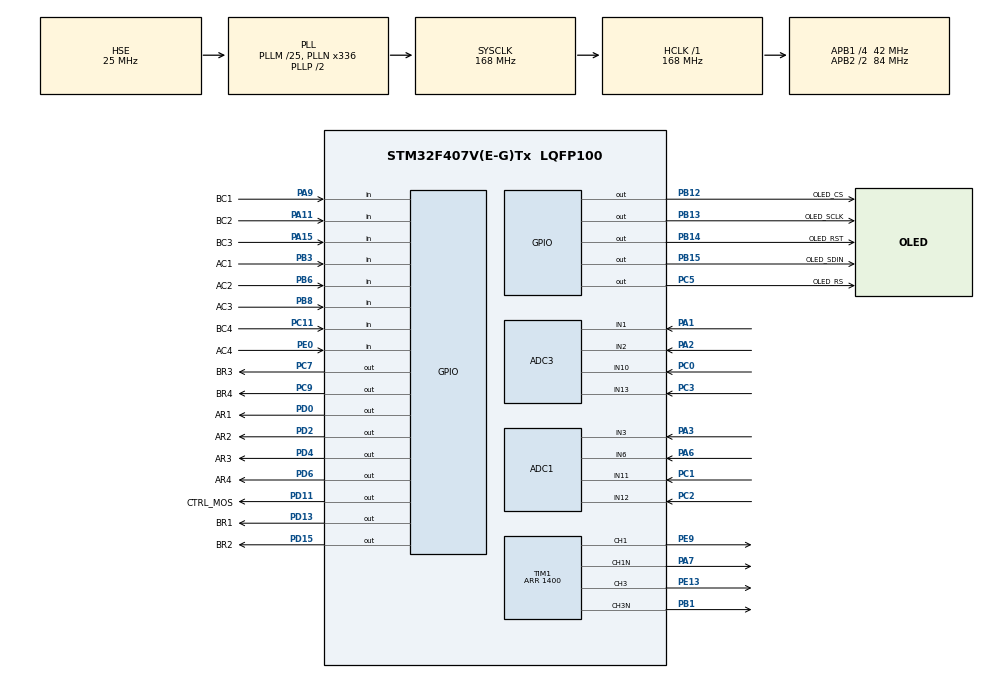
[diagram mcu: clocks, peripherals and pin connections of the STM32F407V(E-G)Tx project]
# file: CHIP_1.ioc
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ADC1.Channel-0\#ChannelRegularConversion=ADC_CHANNEL_3
ADC1.Channel-1\#ChannelRegularConversion=ADC_CHANNEL_3
ADC1.Channel-2\#ChannelRegularConversion=ADC_CHANNEL_11
ADC1.Channel-3\#ChannelRegularConversion=ADC_CHANNEL_12
ADC1.ClockPrescaler=ADC_CLOCK_SYNC_PCLK_DIV8
ADC1.DMAContinuousRequests=ENABLE
ADC1.EOCSelection=ADC_EOC_SEQ_CONV
ADC1.ExternalTrigConv=ADC_EXTERNALTRIGCONV_T1_CC2
ADC1.NbrOfConversion=4
ADC1.NbrOfConversionFlag=1
ADC1.Rank-0\#ChannelRegularConversion=1
ADC1.Rank-1\#ChannelRegularConversion=2
ADC1.Rank-2\#ChannelRegularConversion=3
ADC1.Rank-3\#ChannelRegularConversion=4
ADC1.SamplingTime-0\#ChannelRegularConversion=ADC_SAMPLETIME_15CYCLES
ADC1.SamplingTime-1\#ChannelRegularConversion=ADC_SAMPLETIME_15CYCLES
ADC1.SamplingTime-2\#ChannelRegularConversion=ADC_SAMPLETIME_15CYCLES
ADC1.SamplingTime-3\#ChannelRegularConversion=ADC_SAMPLETIME_15CYCLES
ADC1.ScanConvMode=ENABLE
ADC1.master=1
ADC3.Channel-0\#ChannelRegularConversion=ADC_CHANNEL_1
ADC3.Channel-1\#ChannelRegularConversion=ADC_CHANNEL_2
ADC3.Channel-2\#ChannelRegularConversion=ADC_CHANNEL_10
ADC3.Channel-3\#ChannelRegularConversion=ADC_CHANNEL_13
ADC3.ClockPrescaler=ADC_CLOCK_SYNC_PCLK_DIV8
ADC3.DMAContinuousRequests=ENABLE
ADC3.EOCSelection=ADC_EOC_SEQ_CONV
ADC3.ExternalTrigConv=ADC_EXTERNALTRIGCONV_T1_CC2
ADC3.NbrOfConversion=4
ADC3.NbrOfConversionFlag=1
ADC3.Rank-0\#ChannelRegularConversion=1
ADC3.Rank-1\#ChannelRegularConversion=2
ADC3.Rank-2\#ChannelRegularConversion=3
ADC3.Rank-3\#ChannelRegularConversion=4
ADC3.SamplingTime-0\#ChannelRegularConversion=ADC_SAMPLETIME_15CYCLES
ADC3.SamplingTime-1\#ChannelRegularConversion=ADC_SAMPLETIME_15CYCLES
ADC3.SamplingTime-2\#ChannelRegularConversion=ADC_SAMPLETIME_15CYCLES
ADC3.SamplingTime-3\#ChannelRegularConversion=ADC_SAMPLETIME_15CYCLES
ADC3.ScanConvMode=ENABLE
Dma.ADC1.0.Direction=DMA_PERIPH_TO_MEMORY
Dma.ADC1.0.FIFOMode=DMA_FIFOMODE_DISABLE
Dma.ADC1.0.Instance=DMA2_Stream0
Dma.ADC1.0.MemDataAlignment=DMA_MDATAALIGN_HALFWORD
Dma.ADC1.0.MemInc=DMA_MINC_ENABLE
Dma.ADC1.0.Mode=DMA_CIRCULAR
Dma.ADC1.0.PeriphDataAlignment=DMA_PDATAALIGN_HALFWORD
Dma.ADC1.0.PeriphInc=DMA_PINC_DISABLE
Dma.ADC1.0.Priority=DMA_PRIORITY_LOW
Dma.ADC3.1.Direction=DMA_PERIPH_TO_MEMORY
Dma.ADC3.1.FIFOMode=DMA_FIFOMODE_DISABLE
Dma.ADC3.1.Instance=DMA2_Stream1
Dma.ADC3.1.MemDataAlignment=DMA_MDATAALIGN_HALFWORD
Dma.ADC3.1.MemInc=DMA_MINC_ENABLE
Dma.ADC3.1.Mode=DMA_CIRCULAR
Dma.ADC3.1.PeriphDataAlignment=DMA_PDATAALIGN_HALFWORD
Dma.ADC3.1.PeriphInc=DMA_PINC_DISABLE
Dma.ADC3.1.Priority=DMA_PRIORITY_LOW
Dma.Request0=ADC1
Dma.Request1=ADC3
FREERTOS.Tasks01=defaultTask,24,512,StartDefaultTask,As weak,NULL,Dynamic,NULL,NULL
FREERTOS.configENABLE_FPU=1
Mcu.Family=STM32F4
Mcu.Name=STM32F407V(E-G)Tx
Mcu.Package=LQFP100
NVIC.DMA2_Stream0_IRQn=true\:5\:0\:false\:false\:true\:true\:false\:true\:true
NVIC.DMA2_Stream1_IRQn=true\:5\:0\:false\:false\:true\:true\:false\:true\:true
NVIC.PriorityGroup=NVIC_PRIORITYGROUP_4
NVIC.TIM2_IRQn=true\:5\:0\:false\:false\:true\:true\:true\:true\:true
NVIC.TIM8_TRG_COM_TIM14_IRQn=true\:15\:0\:false\:false\:true\:false\:false\:true\:true
NVIC.TimeBase=TIM8_TRG_COM_TIM14_IRQn
NVIC.TimeBaseIP=TIM14
PA0-WKUP.Mode=SYS_WakeUp0
PA0-WKUP.Signal=SYS_WKUP
PA1.Signal=ADCx_IN1
PA11.GPIO_Label=BC2
PA11.GPIO_PuPd=GPIO_PULLUP
PA11.Signal=GPIO_Input
PA13.Mode=Serial_Wire
PA13.Signal=SYS_JTMS-SWDIO
PA14.Mode=Serial_Wire
PA14.Signal=SYS_JTCK-SWCLK
PA15.GPIO_Label=BC3
PA15.GPIO_PuPd=GPIO_PULLUP
PA15.Signal=GPIO_Input
PA2.Signal=ADCx_IN2
PA3.Signal=ADCx_IN3
PA6.Signal=ADCx_IN6
PA7.Mode=PWM Generation1 CH1 CH1N
PA7.Signal=TIM1_CH1N
PA9.GPIO_Label=BC1
PA9.GPIO_PuPd=GPIO_PULLUP
PA9.Signal=GPIO_Input
PB1.Mode=PWM Generation3 CH3 CH3N
PB1.Signal=TIM1_CH3N
PB12.GPIO_Label=OLED_CS
PB12.GPIO_PuPd=GPIO_PULLUP
PB12.GPIO_Speed=GPIO_SPEED_FREQ_VERY_HIGH
PB12.Signal=GPIO_Output
PB13.GPIO_Label=OLED_SCLK
PB13.GPIO_PuPd=GPIO_PULLUP
PB13.GPIO_Speed=GPIO_SPEED_FREQ_VERY_HIGH
PB13.Signal=GPIO_Output
PB14.GPIO_Label=OLED_RST
PB14.GPIO_PuPd=GPIO_PULLUP
PB14.GPIO_Speed=GPIO_SPEED_FREQ_VERY_HIGH
PB14.Signal=GPIO_Output
PB15.GPIO_Label=OLED_SDIN
PB15.GPIO_PuPd=GPIO_PULLUP
PB15.GPIO_Speed=GPIO_SPEED_FREQ_VERY_HIGH
PB15.Signal=GPIO_Output
PB3.GPIO_Label=AC1
PB3.GPIO_PuPd=GPIO_PULLUP
PB3.Signal=GPIO_Input
PB6.GPIO_Label=AC2
PB6.GPIO_PuPd=GPIO_PULLUP
PB6.Signal=GPIO_Input
PB8.GPIO_Label=AC3
PB8.GPIO_PuPd=GPIO_PULLUP
PB8.Signal=GPIO_Input
PC0.Signal=ADCx_IN10
PC1.Signal=ADCx_IN11
PC11.GPIO_Label=BC4
PC11.GPIO_PuPd=GPIO_PULLUP
PC11.Signal=GPIO_Input
PC2.Signal=ADCx_IN12
PC3.Signal=ADCx_IN13
PC5.GPIO_Label=OLED_RS
PC5.GPIO_PuPd=GPIO_PULLUP
PC5.GPIO_Speed=GPIO_SPEED_FREQ_VERY_HIGH
PC5.Signal=GPIO_Output
PC7.GPIO_Label=BR3
PC7.GPIO_ModeDefaultOutputPP=GPIO_MODE_OUTPUT_PP
PC7.GPIO_PuPd=GPIO_PULLUP
PC7.GPIO_Speed=GPIO_SPEED_FREQ_VERY_HIGH
PC7.PinState=GPIO_PIN_SET
PC7.Signal=GPIO_Output
PC9.GPIO_Label=BR4
PC9.GPIO_ModeDefaultOutputPP=GPIO_MODE_OUTPUT_PP
PC9.GPIO_PuPd=GPIO_PULLUP
PC9.GPIO_Speed=GPIO_SPEED_FREQ_VERY_HIGH
PC9.PinState=GPIO_PIN_SET
PC9.Signal=GPIO_Output
PD0.GPIO_Label=AR1
PD0.GPIO_PuPd=GPIO_PULLUP
PD0.GPIO_Speed=GPIO_SPEED_FREQ_VERY_HIGH
PD0.PinState=GPIO_PIN_SET
PD0.Signal=GPIO_Output
PD11.GPIO_Label=CTRL_MOS
PD11.GPIO_PuPd=GPIO_PULLUP
PD11.GPIO_Speed=GPIO_SPEED_FREQ_VERY_HIGH
PD11.PinState=GPIO_PIN_SET
PD11.Signal=GPIO_Output
PD13.GPIO_Label=BR1
PD13.GPIO_PuPd=GPIO_PULLUP
PD13.GPIO_Speed=GPIO_SPEED_FREQ_VERY_HIGH
PD13.PinState=GPIO_PIN_SET
PD13.Signal=GPIO_Output
PD15.GPIO_Label=BR2
PD15.GPIO_PuPd=GPIO_PULLUP
PD15.GPIO_Speed=GPIO_SPEED_FREQ_VERY_HIGH
PD15.PinState=GPIO_PIN_SET
PD15.Signal=GPIO_Output
PD2.GPIO_Label=AR2
PD2.GPIO_PuPd=GPIO_PULLUP
PD2.GPIO_Speed=GPIO_SPEED_FREQ_VERY_HIGH
PD2.PinState=GPIO_PIN_SET
PD2.Signal=GPIO_Output
PD4.GPIO_Label=AR3
PD4.GPIO_PuPd=GPIO_PULLUP
PD4.GPIO_Speed=GPIO_SPEED_FREQ_VERY_HIGH
PD4.PinState=GPIO_PIN_SET
PD4.Signal=GPIO_Output
PD6.GPIO_Label=AR4
PD6.GPIO_PuPd=GPIO_PULLUP
PD6.GPIO_Speed=GPIO_SPEED_FREQ_VERY_HIGH
PD6.PinState=GPIO_PIN_SET
PD6.Signal=GPIO_Output
PE0.GPIO_Label=AC4
PE0.GPIO_PuPd=GPIO_PULLUP
PE0.Signal=GPIO_Input
PE13.Signal=S_TIM1_CH3
PE9.Signal=S_TIM1_CH1
PH0-OSC_IN.Mode=HSE-External-Oscillator
PH0-OSC_IN.Signal=RCC_OSC_IN
PH1-OSC_OUT.Mode=HSE-External-Oscillator
PH1-OSC_OUT.Signal=RCC_OSC_OUT
ProjectManager.HeapSize=0x200
ProjectManager.StackSize=0x400
ProjectManager.TargetToolchain=Makefile
RCC.48MHZClocksFreq_Value=84000000
RCC.AHBFreq_Value=168000000
RCC.APB1CLKDivider=RCC_HCLK_DIV4
RCC.APB1Freq_Value=42000000
RCC.APB1TimFreq_Value=84000000
RCC.APB2CLKDivider=RCC_HCLK_DIV2
RCC.APB2Freq_Value=84000000
RCC.APB2TimFreq_Value=168000000
RCC.CortexFreq_Value=168000000
RCC.HCLKFreq_Value=168000000
RCC.HSE_VALUE=25000000
RCC.HSI_VALUE=16000000
RCC.LSE_VALUE=32768
RCC.PLLM=25
RCC.PLLN=336
RCC.PLLSourceVirtual=RCC_PLLSOURCE_HSE
RCC.SYSCLKFreq_VALUE=168000000
RCC.SYSCLKSource=RCC_SYSCLKSOURCE_PLLCLK
RCC.VCOOutputFreq_Value=336000000
SH.ADCx_IN1.0=ADC3_IN1,IN1
SH.ADCx_IN10.0=ADC3_IN10,IN10
SH.ADCx_IN11.0=ADC1_IN11,IN11
SH.ADCx_IN12.0=ADC1_IN12,IN12
SH.ADCx_IN13.0=ADC3_IN13,IN13
SH.ADCx_IN2.0=ADC3_IN2,IN2
SH.ADCx_IN3.0=ADC1_IN3,IN3
SH.ADCx_IN6.0=ADC1_IN6,IN6
SH.S_TIM1_CH1.0=TIM1_CH1,PWM Generation1 CH1 CH1N
SH.S_TIM1_CH3.0=TIM1_CH3,PWM Generation3 CH3 CH3N
TIM1.Channel-PWM\ Generation1\ CH1\ CH1N=TIM_CHANNEL_1
TIM1.Channel-PWM\ Generation2\ No\ Output=TIM_CHANNEL_2
TIM1.Channel-PWM\ Generation3\ CH3\ CH3N=TIM_CHANNEL_3
TIM1.ClockDivision=TIM_CLOCKDIVISION_DIV1
TIM1.CounterMode=TIM_COUNTERMODE_CENTERALIGNED1
TIM1.DeadTime=0
TIM1.Period=1400
TIM1.Pulse-PWM\ Generation1\ CH1\ CH1N=700
TIM1.Pulse-PWM\ Generation2\ No\ Output=1
TIM2.Channel-PWM\ Generation4\ No\ Output=TIM_CHANNEL_4
TIM2.Period=1400-1
TIM2.Pulse-PWM\ Generation4\ No\ Output=700
VP_FREERTOS_VS_CMSIS_V2.Mode=CMSIS_V2
VP_SYS_VS_tim14.Mode=TIM14
VP_TIM1_VS_ClockSourceINT.Mode=Internal
VP_TIM1_VS_no_output2.Mode=PWM Generation2 No Output
VP_TIM2_VS_ClockSourceINT.Mode=Internal
VP_TIM2_VS_no_output4.Mode=PWM Generation4 No Output
board=custom

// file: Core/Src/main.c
/* USER CODE BEGIN Header */
/**
  ******************************************************************************
  * @file           : main.c
  * @brief          : Main program body
  ******************************************************************************
  * @attention
  *
  * Copyright (c) 2023 STMicroelectronics.
  * All rights reserved.
  *
  * This software is licensed under terms that can be found in the LICENSE file
  * in the root directory of this software component.
  * If no LICENSE file comes with this software, it is provided AS-IS.
  *
  ******************************************************************************
  */
/* USER CODE END Header */
#include "main.h"
#include "cmsis_os.h"
#include "adc.h"
#include "dma.h"
#include "tim.h"
#include "gpio.h"

/* USER CODE BEGIN Includes */
#include "oled.h"
#include "button.h"
#include "button_display.h"
/* USER CODE END Includes */

void SystemClock_Config(void);
void MX_FREERTOS_Init(void);

int main(void)
{

  /* MCU Configuration--------------------------------------------------------*/

  /* Reset of all peripherals, Initializes the Flash interface and the Systick. */
  HAL_Init();

  /* Configure the system clock */
  SystemClock_Config();

  /* Initialize all configured peripherals */
  MX_GPIO_Init();
  MX_DMA_Init();
  MX_ADC1_Init();
  MX_TIM2_Init();
  MX_TIM1_Init();
  MX_ADC3_Init();
  /* USER CODE BEGIN 2 */
  OLED_Init();
  DISPLAY_PID_SYMBLE();
  /* USER CODE END 2 */

  /* Init scheduler */
  osKernelInitialize();

  /* Call init function for freertos objects (in cmsis_os2.c) */
  MX_FREERTOS_Init();

  /* Start scheduler */
  osKernelStart();

  /* We should never get here as control is now taken by the scheduler */

  /* Infinite loop */
  while (1)
  {

    /* USER CODE BEGIN 3 */
    READ_BUTTON_A();
    READ_BUTTON_B();
    DISPLAY_PID();
    OLED_Refresh_Gram();
    HAL_Delay(50-1);
  }
  /* USER CODE END 3 */
}

void SystemClock_Config(void)
{
  RCC_OscInitTypeDef RCC_OscInitStruct = {0};
  RCC_ClkInitTypeDef RCC_ClkInitStruct = {0};

  /** Configure the main internal regulator output voltage
  */
  __HAL_RCC_PWR_CLK_ENABLE();
  __HAL_PWR_VOLTAGESCALING_CONFIG(PWR_REGULATOR_VOLTAGE_SCALE1);

  /** Initializes the RCC Oscillators according to the specified parameters
  * in the RCC_OscInitTypeDef structure.
  */
  RCC_OscInitStruct.OscillatorType = RCC_OSCILLATORTYPE_HSE;
  RCC_OscInitStruct.HSEState = RCC_HSE_ON;
  RCC_OscInitStruct.PLL.PLLState = RCC_PLL_ON;
  RCC_OscInitStruct.PLL.PLLSource = RCC_PLLSOURCE_HSE;
  RCC_OscInitStruct.PLL.PLLM = 25;
  RCC_OscInitStruct.PLL.PLLN = 336;
  RCC_OscInitStruct.PLL.PLLP = RCC_PLLP_DIV2;
  RCC_OscInitStruct.PLL.PLLQ = 4;
  if (HAL_RCC_OscConfig(&RCC_OscInitStruct) != HAL_OK)
  {
    Error_Handler();
  }

  /** Initializes the CPU, AHB and APB buses clocks
  */
  RCC_ClkInitStruct.ClockType = RCC_CLOCKTYPE_HCLK|RCC_CLOCKTYPE_SYSCLK
                              |RCC_CLOCKTYPE_PCLK1|RCC_CLOCKTYPE_PCLK2;
  RCC_ClkInitStruct.SYSCLKSource = RCC_SYSCLKSOURCE_PLLCLK;
  RCC_ClkInitStruct.AHBCLKDivider = RCC_SYSCLK_DIV1;
  RCC_ClkInitStruct.APB1CLKDivider = RCC_HCLK_DIV4;
  RCC_ClkInitStruct.APB2CLKDivider = RCC_HCLK_DIV2;

  if (HAL_RCC_ClockConfig(&RCC_ClkInitStruct, FLASH_LATENCY_5) != HAL_OK)
  {
    Error_Handler();
  }
}

void HAL_TIM_PeriodElapsedCallback(TIM_HandleTypeDef *htim)
{
  if (htim->Instance == TIM14) {
    HAL_IncTick();
  }
}

void Error_Handler(void)
{
  __disable_irq();
  while (1)
  {
  }
}

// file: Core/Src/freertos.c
/* USER CODE BEGIN Header */
/**
  ******************************************************************************
  * File Name          : freertos.c
  * Description        : Code for freertos applications
  ******************************************************************************
  * @attention
  *
  * Copyright (c) 2023 STMicroelectronics.
  * All rights reserved.
  *
  * This software is licensed under terms that can be found in the LICENSE file
  * in the root directory of this software component.
  * If no LICENSE file comes with this software, it is provided AS-IS.
  *
  ******************************************************************************
  */
/* USER CODE END Header */

#include "FreeRTOS.h"
#include "task.h"
#include "main.h"
#include "cmsis_os.h"

/* Definitions for defaultTask */
osThreadId_t defaultTaskHandle;
const osThreadAttr_t defaultTask_attributes = {
  .name = "defaultTask",
  .stack_size = 512 * 4,
  .priority = (osPriority_t) osPriorityNormal,
};

void StartDefaultTask(void *argument);

void MX_FREERTOS_Init(void); /* (MISRA C 2004 rule 8.1) */

void MX_FREERTOS_Init(void) {

  /* Create the thread(s) */
  /* creation of defaultTask */
  defaultTaskHandle = osThreadNew(StartDefaultTask, NULL, &defaultTask_attributes);

}

__weak void StartDefaultTask(void *argument)
{
  for(;;)
  {
    osDelay(1);
  }
}
